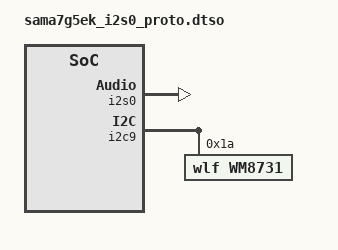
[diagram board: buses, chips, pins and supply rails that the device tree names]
// SPDX-License-Identifier: (GPL-2.0+ OR MIT)
/*
 * Device Tree file for SAMA7G5-EK board
 * overlay blob for I2S with PROTO board. The blob uses i2s0 and i2c9.
 *
 * Copyright (C) 2020 Microchip Technology Inc. and its subsidiaries
 * Author: Codrin Ciubotariu <codrin.ciubotariu@microchip.com>
 *
 */
/dts-v1/;
/plugin/;

#include "dt-bindings/sound/microchip,asrc-card.h"
#include "sama7g5-pinfunc.h"

&i2s0 {
	status = "okay";
};

&i2c9 {
	#address-cells = <1>;
	#size-cells = <0>;
	wm8731: wm8731@1a {
		compatible = "wlf,wm8731";
		reg = <0x1a>;
		#sound-dai-cells = <0>;
	};
};

&sound {
	#address-cells = <1>;
	#size-cells = <0>;

	/* make sure id from dai-link@<id> and reg are unique */
	microchip,dai-link@3 {
		reg = <3>;
		microchip,format = "i2s";
		microchip,frame-master = <&dailink3_master>;
		microchip,bitclock-master = <&dailink3_master>;
		microchip,convert-channels = <2>;
		microchip,convert-rate = <48000>;
		microchip,convert-sample-format = <MCHP_ASRC_PCM_FORMAT_S24_LE>;
		dailink3_master: cpu {		/* make sure label is unique */
			sound-dai = <&i2s0>;
		};
		codec {
			sound-dai = <&wm8731>;
		};
	};
};
